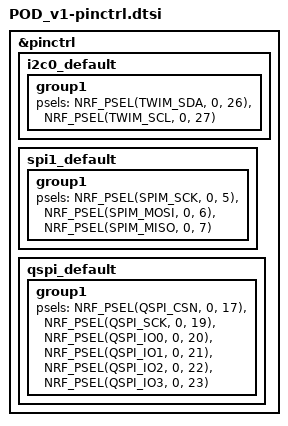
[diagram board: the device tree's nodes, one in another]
&pinctrl {
	i2c0_default: i2c0_default {
		group1 {
			psels = <NRF_PSEL(TWIM_SDA, 0, 26)>, <NRF_PSEL(TWIM_SCL, 0, 27)>;
		};
	};
	spi1_default: spi1_default {
		group1 {
			psels = <NRF_PSEL(SPIM_SCK, 0, 5)>,
					<NRF_PSEL(SPIM_MOSI, 0, 6)>,
					<NRF_PSEL(SPIM_MISO, 0, 7)>;
		};
	};
	qspi_default: qspi_default {
		group1 {
			psels = <NRF_PSEL(QSPI_CSN, 0, 17)>,
					<NRF_PSEL(QSPI_SCK, 0, 19)>,
					<NRF_PSEL(QSPI_IO0, 0, 20)>,
					<NRF_PSEL(QSPI_IO1, 0, 21)>,
					<NRF_PSEL(QSPI_IO2, 0, 22)>,
					<NRF_PSEL(QSPI_IO3, 0, 23)>;
		};
	};
};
